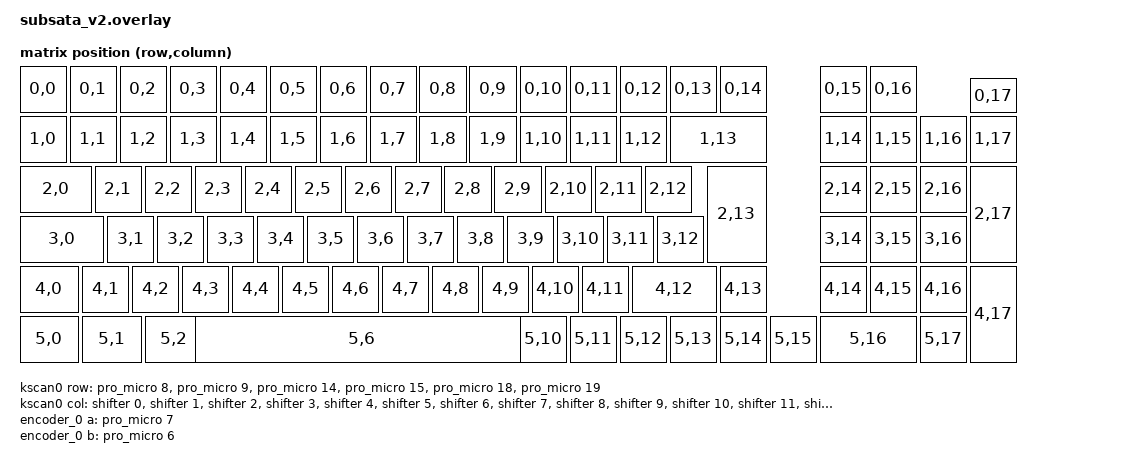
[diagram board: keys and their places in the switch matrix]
/* Generated by ZMK Editor from subsata_v2.editor.json. */

#include <dt-bindings/zmk/matrix_transform.h>
#include <physical_layouts.dtsi>
#include <dt-bindings/led/led.h>

/ {
    chosen {
        zmk,kscan = &kscan0;
        zmk,physical-layout = &subsata_v2_layout;
    };

    kscan0: kscan {
        compatible = "zmk,kscan-gpio-matrix";
        wakeup-source;
        diode-direction = "col2row";

        row-gpios
            = <&pro_micro  8 (GPIO_ACTIVE_HIGH | GPIO_PULL_DOWN)>
            , <&pro_micro  9 (GPIO_ACTIVE_HIGH | GPIO_PULL_DOWN)>
            , <&pro_micro 14 (GPIO_ACTIVE_HIGH | GPIO_PULL_DOWN)>
            , <&pro_micro 15 (GPIO_ACTIVE_HIGH | GPIO_PULL_DOWN)>
            , <&pro_micro 18 (GPIO_ACTIVE_HIGH | GPIO_PULL_DOWN)>
            , <&pro_micro 19 (GPIO_ACTIVE_HIGH | GPIO_PULL_DOWN)>
            ;

        col-gpios
            = <&shifter  0 GPIO_ACTIVE_HIGH>
            , <&shifter  1 GPIO_ACTIVE_HIGH>
            , <&shifter  2 GPIO_ACTIVE_HIGH>
            , <&shifter  3 GPIO_ACTIVE_HIGH>
            , <&shifter  4 GPIO_ACTIVE_HIGH>
            , <&shifter  5 GPIO_ACTIVE_HIGH>
            , <&shifter  6 GPIO_ACTIVE_HIGH>
            , <&shifter  7 GPIO_ACTIVE_HIGH>
            , <&shifter  8 GPIO_ACTIVE_HIGH>
            , <&shifter  9 GPIO_ACTIVE_HIGH>
            , <&shifter 10 GPIO_ACTIVE_HIGH>
            , <&shifter 11 GPIO_ACTIVE_HIGH>
            , <&shifter 12 GPIO_ACTIVE_HIGH>
            , <&shifter 13 GPIO_ACTIVE_HIGH>
            , <&shifter 14 GPIO_ACTIVE_HIGH>
            , <&shifter 15 GPIO_ACTIVE_HIGH>
            , <&pro_micro 20 GPIO_ACTIVE_HIGH>
            , <&pro_micro 21 GPIO_ACTIVE_HIGH>
            ;
    };

    default_transform: keymap_transform_0 {
        compatible = "zmk,matrix-transform";
        rows = <6>;
        columns = <18>;
        map = <
RC(0,0)  RC(0,1)  RC(0,2)           RC(0,3)  RC(0,4)  RC(0,5)           RC(0,6)  RC(0,7)  RC(0,8)           RC(0,9)  RC(0,10) RC(0,11) RC(0,12) RC(0,13) RC(0,14)          RC(0,15) RC(0,16)          RC(0,17)
RC(1,0)  RC(1,1)  RC(1,2)           RC(1,3)  RC(1,4)  RC(1,5)           RC(1,6)  RC(1,7)  RC(1,8)           RC(1,9)  RC(1,10) RC(1,11) RC(1,12)          RC(1,13)          RC(1,14) RC(1,15) RC(1,16) RC(1,17)
RC(2,0)           RC(2,1)  RC(2,2)  RC(2,3)           RC(2,4)  RC(2,5)  RC(2,6)           RC(2,7)  RC(2,8)  RC(2,9)           RC(2,10) RC(2,11) RC(2,12) RC(2,13)          RC(2,14) RC(2,15) RC(2,16) RC(2,17)
RC(3,0)           RC(3,1)  RC(3,2)           RC(3,3)  RC(3,4)  RC(3,5)           RC(3,6)  RC(3,7)  RC(3,8)           RC(3,9)  RC(3,10) RC(3,11) RC(3,12)                   RC(3,14) RC(3,15) RC(3,16)
RC(4,0)  RC(4,1)           RC(4,2)  RC(4,3)  RC(4,4)           RC(4,5)  RC(4,6)  RC(4,7)           RC(4,8)  RC(4,9)  RC(4,10)          RC(4,11) RC(4,12) RC(4,13)          RC(4,14) RC(4,15) RC(4,16) RC(4,17)
RC(5,0)  RC(5,1)           RC(5,2)                                      RC(5,6)                                      RC(5,10) RC(5,11) RC(5,12) RC(5,13) RC(5,14)          RC(5,16)          RC(5,17)
                                                                                                                                                                  RC(5,15)
        >;
    };

    encoder_0: encoder_0 {
        compatible = "alps,ec11";
        a-gpios = <&pro_micro  7 (GPIO_ACTIVE_HIGH | GPIO_PULL_UP)>;
        b-gpios = <&pro_micro  6 (GPIO_ACTIVE_HIGH | GPIO_PULL_UP)>;
        steps = <80>;
    };

    sensors: sensors {
        compatible = "zmk,keymap-sensors";
        sensors = <&encoder_0>;
        triggers-per-rotation = <20>;
    };

    subsata_v2_layout: subsata_v2_layout {
        compatible = "zmk,physical-layout";
        display-name = "SubSata V2";
        transform = <&default_transform>;

        keys  //                     w   h    x    y     rot   rx   ry
            = <&key_physical_attrs 100 100    0    0      0   25   25>
            , <&key_physical_attrs 100 100  100    0      0    0    0>
            , <&key_physical_attrs 100 100  200    0      0    0    0>
            , <&key_physical_attrs 100 100  300    0      0    0    0>
            , <&key_physical_attrs 100 100  400    0      0    0    0>
            , <&key_physical_attrs 100 100  500    0      0    0    0>
            , <&key_physical_attrs 100 100  600    0      0    0    0>
            , <&key_physical_attrs 100 100  700    0      0    0    0>
            , <&key_physical_attrs 100 100  800    0      0    0    0>
            , <&key_physical_attrs 100 100  900    0      0    0    0>
            , <&key_physical_attrs 100 100 1000    0      0    0    0>
            , <&key_physical_attrs 100 100 1100    0      0    0    0>
            , <&key_physical_attrs 100 100 1200    0      0    0    0>
            , <&key_physical_attrs 100 100 1300    0      0    0    0>
            , <&key_physical_attrs 100 100 1400    0      0    0    0>
            , <&key_physical_attrs 100 100 1600    0      0    0    0>
            , <&key_physical_attrs 100 100 1700    0      0    0    0>
            , <&key_physical_attrs 100  75 1900   25      0    0    0>
            , <&key_physical_attrs 100 100    0  100      0    0    0>
            , <&key_physical_attrs 100 100  100  100      0    0    0>
            , <&key_physical_attrs 100 100  200  100      0    0    0>
            , <&key_physical_attrs 100 100  300  100      0    0    0>
            , <&key_physical_attrs 100 100  400  100      0    0    0>
            , <&key_physical_attrs 100 100  500  100      0    0    0>
            , <&key_physical_attrs 100 100  600  100      0    0    0>
            , <&key_physical_attrs 100 100  700  100      0    0    0>
            , <&key_physical_attrs 100 100  800  100      0    0    0>
            , <&key_physical_attrs 100 100  900  100      0    0    0>
            , <&key_physical_attrs 100 100 1000  100      0    0    0>
            , <&key_physical_attrs 100 100 1100  100      0    0    0>
            , <&key_physical_attrs 100 100 1200  100      0    0    0>
            , <&key_physical_attrs 200 100 1300  100      0    0    0>
            , <&key_physical_attrs 100 100 1600  100      0    0    0>
            , <&key_physical_attrs 100 100 1700  100      0    0    0>
            , <&key_physical_attrs 100 100 1800  100      0    0    0>
            , <&key_physical_attrs 100 100 1900  100      0    0    0>
            , <&key_physical_attrs 150 100    0  200      0    0    0>
            , <&key_physical_attrs 100 100  150  200      0    0    0>
            , <&key_physical_attrs 100 100  250  200      0    0    0>
            , <&key_physical_attrs 100 100  350  200      0    0    0>
            , <&key_physical_attrs 100 100  450  200      0    0    0>
            , <&key_physical_attrs 100 100  550  200      0    0    0>
            , <&key_physical_attrs 100 100  650  200      0    0    0>
            , <&key_physical_attrs 100 100  750  200      0    0    0>
            , <&key_physical_attrs 100 100  850  200      0    0    0>
            , <&key_physical_attrs 100 100  950  200      0    0    0>
            , <&key_physical_attrs 100 100 1050  200      0    0    0>
            , <&key_physical_attrs 100 100 1150  200      0    0    0>
            , <&key_physical_attrs 100 100 1250  200      0    0    0>
            , <&key_physical_attrs 125 200 1375  200      0    0    0>
            , <&key_physical_attrs 100 100 1600  200      0    0    0>
            , <&key_physical_attrs 100 100 1700  200      0    0    0>
            , <&key_physical_attrs 100 100 1800  200      0    0    0>
            , <&key_physical_attrs 100 200 1900  200      0    0    0>
            , <&key_physical_attrs 175 100    0  300      0    0    0>
            , <&key_physical_attrs 100 100  175  300      0    0    0>
            , <&key_physical_attrs 100 100  275  300      0    0    0>
            , <&key_physical_attrs 100 100  375  300      0    0    0>
            , <&key_physical_attrs 100 100  475  300      0    0    0>
            , <&key_physical_attrs 100 100  575  300      0    0    0>
            , <&key_physical_attrs 100 100  675  300      0    0    0>
            , <&key_physical_attrs 100 100  775  300      0    0    0>
            , <&key_physical_attrs 100 100  875  300      0    0    0>
            , <&key_physical_attrs 100 100  975  300      0    0    0>
            , <&key_physical_attrs 100 100 1075  300      0    0    0>
            , <&key_physical_attrs 100 100 1175  300      0    0    0>
            , <&key_physical_attrs 100 100 1275  300      0    0    0>
            , <&key_physical_attrs 100 100 1600  300      0    0    0>
            , <&key_physical_attrs 100 100 1700  300      0    0    0>
            , <&key_physical_attrs 100 100 1800  300      0    0    0>
            , <&key_physical_attrs 125 100    0  400      0    0    0>
            , <&key_physical_attrs 100 100  125  400      0    0    0>
            , <&key_physical_attrs 100 100  225  400      0    0    0>
            , <&key_physical_attrs 100 100  325  400      0    0    0>
            , <&key_physical_attrs 100 100  425  400      0    0    0>
            , <&key_physical_attrs 100 100  525  400      0    0    0>
            , <&key_physical_attrs 100 100  625  400      0    0    0>
            , <&key_physical_attrs 100 100  725  400      0    0    0>
            , <&key_physical_attrs 100 100  825  400      0    0    0>
            , <&key_physical_attrs 100 100  925  400      0    0    0>
            , <&key_physical_attrs 100 100 1025  400      0    0    0>
            , <&key_physical_attrs 100 100 1125  400      0    0    0>
            , <&key_physical_attrs 175 100 1225  400      0    0    0>
            , <&key_physical_attrs 100 100 1400  400      0    0    0>
            , <&key_physical_attrs 100 100 1600  400      0    0    0>
            , <&key_physical_attrs 100 100 1700  400      0    0    0>
            , <&key_physical_attrs 100 100 1800  400      0    0    0>
            , <&key_physical_attrs 100 200 1900  400      0    0    0>
            , <&key_physical_attrs 125 100    0  500      0    0    0>
            , <&key_physical_attrs 125 100  125  500      0    0    0>
            , <&key_physical_attrs 125 100  250  500      0    0    0>
            , <&key_physical_attrs 675 100  350  500      0    0    0>
            , <&key_physical_attrs 100 100 1000  500      0    0    0>
            , <&key_physical_attrs 100 100 1100  500      0    0    0>
            , <&key_physical_attrs 100 100 1200  500      0    0    0>
            , <&key_physical_attrs 100 100 1300  500      0    0    0>
            , <&key_physical_attrs 100 100 1400  500      0    0    0>
            , <&key_physical_attrs 200 100 1600  500      0    0    0>
            , <&key_physical_attrs 100 100 1800  500      0    0    0>
            , <&key_physical_attrs 100 100 1500  500      0    0    0>
            ;
    };
};

&pinctrl {
    nice_view_spi_default: nice_view_spi_default {
        group1 {
            psels = <NRF_PSEL(SPIM_SCK, 0, 20)>,
                <NRF_PSEL(SPIM_MOSI, 0, 17)>;
        };
    };
    nice_view_spi_sleep: nice_view_spi_sleep {
        group1 {
            psels = <NRF_PSEL(SPIM_SCK, 0, 20)>,
                <NRF_PSEL(SPIM_MOSI, 0, 17)>;
            low-power-enable;
        };
    };
};

nice_view_spi: &pro_micro_spi {
    status = "okay";
    compatible = "nordic,nrf-spim";
    pinctrl-0 = <&nice_view_spi_default>;
    pinctrl-1 = <&nice_view_spi_sleep>;
    pinctrl-names = "default", "sleep";
    cs-gpios = <&pro_micro 1 GPIO_ACTIVE_HIGH>, <&pro_micro 0 GPIO_ACTIVE_LOW>;

    shifter: 595@1 {
        compatible = "zmk,gpio-595";
        status = "okay";
        gpio-controller;
        spi-max-frequency = <1000000>;
        reg = <1>;
        #gpio-cells = <2>;
        ngpios = <16>;
    };
};

&pro_micro_i2c {
    status = "disabled";
};

/ {
    chosen {
        zmk,underglow = &led_strip;
    };
};

&pinctrl {
    led_spi_default: led_spi_default {
        group1 {
            psels = <NRF_PSEL(SPIM_MOSI, 0, 22)>;
        };
    };
    led_spi_sleep: led_spi_sleep {
        group1 {
            psels = <NRF_PSEL(SPIM_MOSI, 0, 22)>;
            low-power-enable;
        };
    };
};

&spi3 {
    status = "okay";
    compatible = "nordic,nrf-spim";
    pinctrl-0 = <&led_spi_default>;
    pinctrl-1 = <&led_spi_sleep>;
    pinctrl-names = "default", "sleep";

    led_strip: ws2812@0 {
        compatible = "worldsemi,ws2812-spi";
        reg = <0>;
        spi-max-frequency = <4000000>;
        chain-length = <20>;
        spi-one-frame = <0x70>;
        spi-zero-frame = <0x40>;
        color-mapping = <LED_COLOR_ID_GREEN LED_COLOR_ID_RED LED_COLOR_ID_BLUE>;
    };
};

/* ZMK's external power switches the LEDs' power; the board's own 3.3V pin stays on. */
&{/EXT_POWER} {
    control-gpios = <&pro_micro 5 GPIO_ACTIVE_HIGH>;
};

&gpio0 {
    vcc_always_on {
        gpio-hog;
        gpios = <13 GPIO_ACTIVE_HIGH>;
        output-high;
    };
};
